# Cortex_M0PLUS register map
Vendor: ARM Ltd.; File version: 1.1
Cortex-M0+ core descriptions, generated from ARM develloper studio
CPU: CM0PLUS r0p0, little endian, MPU, no FPU, vendor SysTick, 8 interrupt priority bits
Registers are 32-bit, read-write, reset 0x0 unless marked. A register's access mark holds for its fields unless they carry their own. Offsets are from the block's base; lines under a group give offsets from that group; [hi:lo] are bit positions; {n}, {i} and the like mark numbered series; 'fields as' and 'values as' point back to an identical list; <NAME> marks a mode.

## Memory map
0x40000000 I2C0 size 0x40 — I2C Bus Controller 0
0x40004000 WDT size 0x10 — Watchdog Timer
0x40004000 CT32B size 0x78 — 32-bit counter/timer 0
0x4000C000 CT16B size 0x78 — 16-bit counter/timer 0
0x40034000 EEPROM size 0x1000 — EEPROM controller
0x40038000 PMU size 0x40 — Power Management Unit
0x4003C000 FLASH size 0x1000 — Flash controller
0x40040000 SPI0 size 0x24 — Serial Peripheral Interface (SPI)
0x40044000 IOCON size 0x30 — IO configuration
0x40048000 SYSCON size 0x3F8 — System Configuration
0x40054000 RTC size 0x34 — Real time clock timer
0x40058000 RFIDNFC size 0x300 — RFID and NFC
0x40060000 TSENS size 0x34 — Temperature Sensor
0x50000000 GPIO size 0x8020 — General Purpose IO
0xE000E010 SysTick size 0x80 — System Timer registers
0xE000E100 NVIC size 0x1A0 — Nested Vectored Interrupt Controller registers

## Interrupts
12 RTCPWREQ (RTC)
15 I2C0
16 CT16B
18 CT32B
19 PMUBOD (PMU)
26 WDT
27 FLASH
28 EEPROM

## WDT — Watchdog Timer
Base 0x40004000
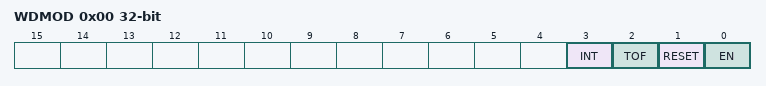
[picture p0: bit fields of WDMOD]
0x00 WDMOD — Watchdog mode register. This register contains the basic mode and status of the Watchdog Timer.
  [3] INT — Watchdog interrupt flag (Read Only, not clearable by software).
  [2] TOF — Watchdog time-out flag. Set when the watchdog timer times out, cleared by software. (Read/write))
  [1] RESET — Watchdog reset enable bit (Set Only). When 1, a watchdog time-out will cause a chip reset.
  [0] EN — Watchdog enable bit (Set Only). When 1, the watchdog timer is running.
0x04 WDTC reset 0xFF — Watchdog timer constant register. This register determines the time-out value.
  [23:0] Count — Watchdog time-out interval
0x08 WDFEED wo reset 0xFFFFFFFF — Watchdog feed sequence register. Writing 0xAA followed by 0x55 to this register reloads the Watchdog timer with the value contained in WDTC.
  [7:0] Feed — Feed value should be 0xAA followed by 0x55
0x0C WDTV reset 0xFF — Watchdog timer value register. This register reads out the current value of the Watchdog timer.
  [23:0] Count ro — Counter timer value

## PMU — Power Management Unit
Base 0x40038000
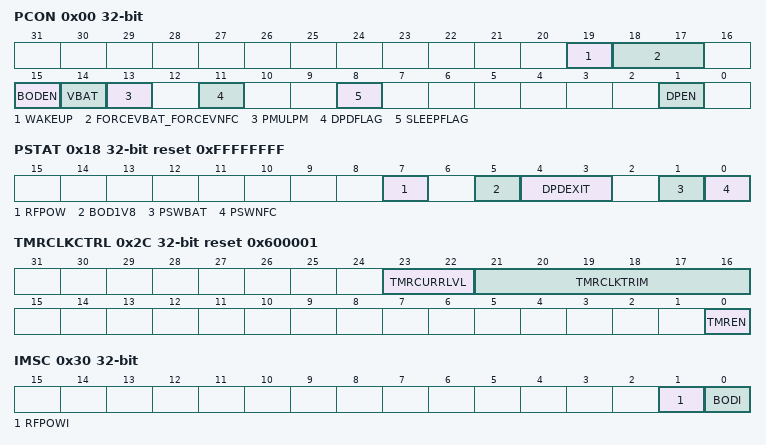
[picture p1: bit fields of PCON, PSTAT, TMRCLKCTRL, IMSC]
0x00 PCON — Power control register
  [19] WAKEUP — enable the WAKEUP function on pin PIO0_0
    0=DISABLED (WAKEUP function not enabled); 1=ENABLED (WAKEUP function assigned to PIO0_0. When selecting this option, PIO0_0 has a weak pull-up to VDD_ALON when in Deep power-down.)
  [18:17] FORCEVBAT_FORCEVNFC — force the power source selection
    1=VBAT_POWER (force to VBAT/external power); 2=NFC_POWER (force to NFC power); 3=AUTO (autoswitching if PMULPM is 0)
  [15] BODEN — Brown-out detector enable
    0=DISABLED (BOD disabled); 1=ENABLED (BOD enabled)
  [14] VBAT — This bit enables the connection of the VBAT pin to VDD, effectively connecting the system to the battery.
    0=NOT_CONNECTED (VBAT not connected to VDD); 1=CONNECTED (VBAT connected to VDD)
  [13] PMULPM — PMU ultra-low-power mod
    0=AUTO (power switches are in automatic mode); 1=FORCED (disable automatic switching (default to external power).)
  [11] DPDFLAG — Deep power-down flag
    0=CLEARED (read: No power-down mode entered / write: no effect); 1=SET (read:deep power-down mode entered / write: clear the deep power-down flag)
  [8] SLEEPFLAG — Sleep mode flag
    0=CLEARED (read: No power-down mode entered / write: no effect); 1=SET (read: sleep/deep-sleep mode entered / write: write 1 to clear SLEEPFLAG)
  [1] DPEN — Deep power-down mode enable
    0=DISABLED (ARM WFI will enter Sleep or Deep-sleep mode (clock to ARM Cortex M0+ core turned off)); 1=ENABLED (ARM WFI will enter Deep-power down mode (ARM Cortex M0+ core powered down))
{0x4+4i} GPREG[{i}] (i=0..4) — General purpose register 0
  [31:0] GPDATA — Data retained during deep power-down mode
0x18 PSTAT reset 0xFFFFFFFF — Power management unit status register
  [7] RFPOW ro — RF field detected
    0=NOT_DETECTED (No field); 1=DETECTED (RF field)
  [5] BOD1V8 ro — BOD detected (VDD less 1.8 V)
    0=VDD larger 1.8 V; 1=VDD less 1.8 V
  [4:3] DPDEXIT ro — reason for exit from Deep-Power Down. Only valid when the DPDFLAG in the PCON register is asserted (1)
    0=POR or RESETN pin asserted; 1=LDO enabled; 2=RTC timer event; 3=WAKEUP pin negative edge detected
  [1] PSWBAT ro — status of battery power selection switch
    0=OPEN (Switch disabled (not conducting)); 1=CLOSED (Switch enabled (conducting))
  [0] PSWNFC ro — Status of NFC power selection switch
    values as PSWBAT
0x20 ACCSTAT — Access status register
  [0] PMU_READY ro — (0) PMU access not possible, (1) PMU access possible
0x24 LDO1V6 reset 0x4 — Analog 1.6 V LDO trimming
  [3:0] TRIM1V6 — Trim value for analog LDO
0x2C TMRCLKCTRL reset 0x600001 — Timer clock control register
  [23:22] TMRCURRLVL — Timer FRO current level selector bits
  [21:16] TMRCLKTRIM — Timer FRO trim value (6-bit)
  [0] TMREN — RTC clock source.
    0=NO_CLOCK; 1=TFRO (32kHz FRO)
0x30 IMSC — interrupt mask set and clear Register
  [1] RFPOWI — software should set this bit to enable an interrupt when RF power is detected.
  [0] BODI — software should set this bit to enable an interrupt when the BOD is triggered.
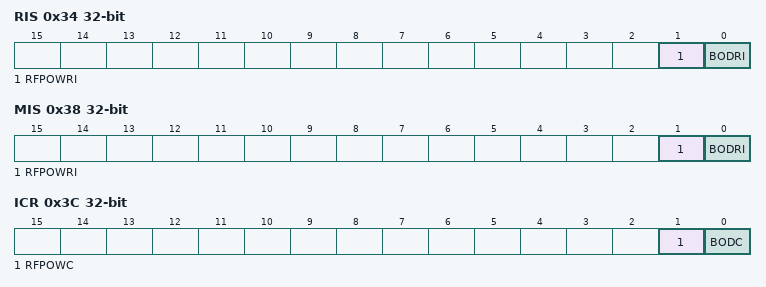
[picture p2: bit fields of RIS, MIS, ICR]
0x34 RIS — raw interrupt status register
  [1] RFPOWRI ro — raw RF power interrupt value
  [0] BODRI ro — raw BOD interrupt value.
0x38 MIS — masked interrupt status register
  fields as RIS
0x3C ICR wo reset not defined — interrupt clear register
  [1] RFPOWC — writing a logic 1 clears the RF power interrupt.
  [0] BODC — writing a logic 1 clears the BOD interrupt.

## Notices in the file
Copyright (c) 2020 STMicroelectronics.
SPDX-License-Identifier: Apache-2.0
Licensed under the Apache License, Version 2.0 (the "License");
you may not use this file except in compliance with the License.
You may obtain a copy of the License at
http://www.apache.org/licenses/LICENSE-2.0
Unless required by applicable law or agreed to in writing, software
distributed under the License is distributed on an "AS IS" BASIS,
WITHOUT WARRANTIES OR CONDITIONS OF ANY KIND, either express or implied.
See the License for the specific language governing permissions and
limitations under the License.
